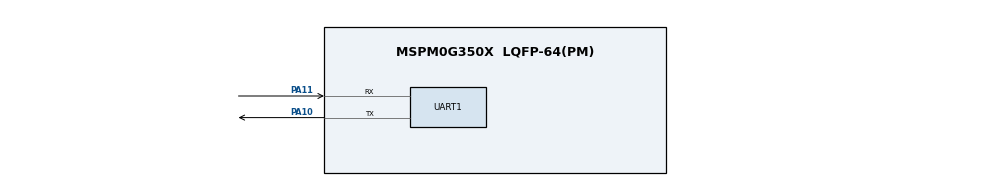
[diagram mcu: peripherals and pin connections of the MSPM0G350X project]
/**
 * @cliArgs --device "MSPM0G350X" --part "Default" --package "LQFP-64(PM)" --product "mspm0_sdk@2.10.00.04"
 * @versions {"tool":"1.26.2+4477"}
 */

/**
 * Import the modules used in this configuration.
 */
const Board         = scripting.addModule("/ti/driverlib/Board");
const SYSTICK       = scripting.addModule("/ti/driverlib/SYSTICK");
const UART          = scripting.addModule("/ti/driverlib/UART", {}, false);
const UART1         = UART.addInstance();
const ProjectConfig = scripting.addModule("/ti/project_config/ProjectConfig");

/**
 * Write custom configuration values to the imported modules.
 */

SYSTICK.periodEnable    = true;
SYSTICK.interruptEnable = true;
SYSTICK.systickEnable   = true;
SYSTICK.period          = 32000;

const SYSCTL = scripting.addModule("/ti/driverlib/SYSCTL", {}, false);

UART1.$name                    = "UART_0";
UART1.targetBaudRate           = 115200;
UART1.peripheral.rxPin.$assign = "PA11";
UART1.peripheral.txPin.$assign = "PA10";
UART1.txPinConfig.$name        = "ti_driverlib_gpio_GPIOPinGeneric0";
UART1.rxPinConfig.$name        = "ti_driverlib_gpio_GPIOPinGeneric1";

/**
 * Pinmux solution for unlocked pins/peripherals. This ensures that minor changes to the automatic solver in a future
 * version of the tool will not impact the pinmux you originally saw.  These lines can be completely deleted in order to
 * re-solve from scratch.
 */
Board.peripheral.$suggestSolution          = "DEBUGSS";
Board.peripheral.swclkPin.$suggestSolution = "PA20";
Board.peripheral.swdioPin.$suggestSolution = "PA19";
SYSCTL.peripheral.$suggestSolution         = "SYSCTL";
UART1.peripheral.$suggestSolution          = "UART0";
